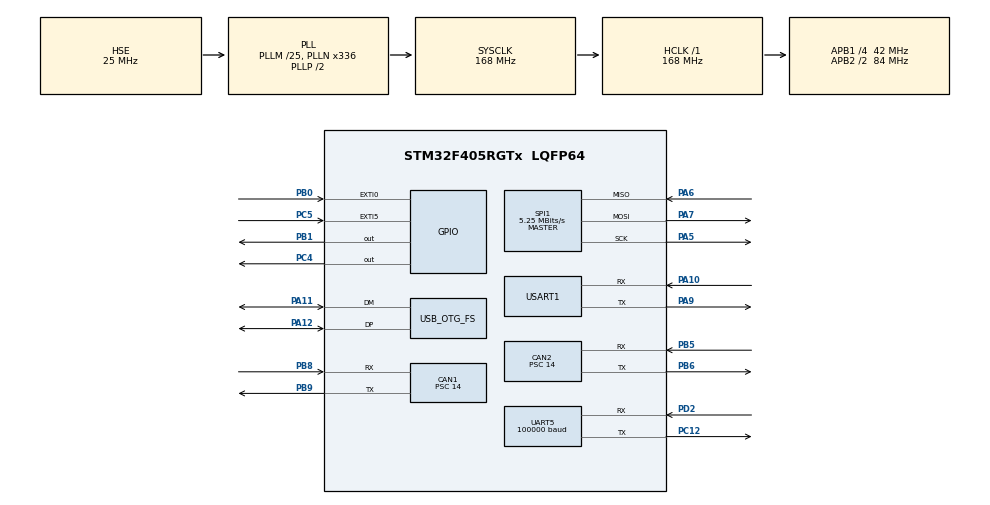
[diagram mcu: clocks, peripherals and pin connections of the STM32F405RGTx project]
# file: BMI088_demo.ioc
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CAN1.CalculateBaudRate=999999
CAN1.CalculateTimeBit=1000
CAN1.CalculateTimeQuantum=333.33333333333337
CAN1.Prescaler=14
CAN2.CalculateBaudRate=999999
CAN2.CalculateTimeBit=1000
CAN2.CalculateTimeQuantum=333.33333333333337
CAN2.Prescaler=14
Dma.Request0=UART5_RX
Dma.UART5_RX.0.Direction=DMA_PERIPH_TO_MEMORY
Dma.UART5_RX.0.FIFOMode=DMA_FIFOMODE_DISABLE
Dma.UART5_RX.0.Instance=DMA1_Stream0
Dma.UART5_RX.0.MemDataAlignment=DMA_MDATAALIGN_BYTE
Dma.UART5_RX.0.MemInc=DMA_MINC_ENABLE
Dma.UART5_RX.0.Mode=DMA_NORMAL
Dma.UART5_RX.0.PeriphDataAlignment=DMA_PDATAALIGN_BYTE
Dma.UART5_RX.0.PeriphInc=DMA_PINC_DISABLE
Dma.UART5_RX.0.Priority=DMA_PRIORITY_VERY_HIGH
FREERTOS.Queues01=BMI088DataQueue,8,4,1,Dynamic,NULL,NULL;VisionDataQueue,16,4,1,Dynamic,NULL,NULL
FREERTOS.Tasks01=UART_Print_Task,10,256,Start_UART_Print_TaskTask,As weak,NULL,Dynamic,NULL,NULL;BMI088_Read_Tas,24,128,Start_BMI088_Read_Task_Task,As weak,NULL,Dynamic,NULL,NULL;VisionProcessTa,25,512,Start_Vision_Process_Task,As weak,NULL,Dynamic,NULL,NULL;CAN_Motor_Task,40,512,Start_CAN_Motor_Task,As weak,NULL,Dynamic,NULL,NULL;RC_Parse_Task,41,512,Start_RC_Parse_Task,As weak,NULL,Dynamic,NULL,NULL;Chassis_CAN_Tas,40,1024,Start_Chassis_CAN_Task,As weak,NULL,Dynamic,NULL,NULL
Mcu.Family=STM32F4
Mcu.Name=STM32F405RGTx
Mcu.Package=LQFP64
NVIC.CAN1_RX0_IRQn=true\:5\:0\:false\:false\:true\:true\:true\:true\:true
NVIC.CAN1_RX1_IRQn=true\:5\:0\:false\:false\:true\:true\:true\:true\:true
NVIC.CAN1_TX_IRQn=true\:5\:0\:false\:false\:true\:true\:true\:true\:true
NVIC.DMA1_Stream0_IRQn=true\:5\:0\:false\:false\:true\:true\:false\:true\:true
NVIC.EXTI0_IRQn=true\:5\:0\:true\:false\:true\:true\:true\:true\:true
NVIC.EXTI9_5_IRQn=true\:5\:0\:true\:false\:true\:true\:true\:true\:true
NVIC.OTG_FS_IRQn=true\:5\:0\:false\:false\:true\:true\:false\:true\:true
NVIC.PriorityGroup=NVIC_PRIORITYGROUP_4
NVIC.TIM1_UP_TIM10_IRQn=true\:15\:0\:false\:false\:true\:false\:false\:true\:true
NVIC.TimeBase=TIM1_UP_TIM10_IRQn
NVIC.TimeBaseIP=TIM1
NVIC.UART5_IRQn=true\:5\:0\:false\:false\:true\:true\:true\:true\:true
PA10.Mode=Asynchronous
PA10.Signal=USART1_RX
PA11.Mode=Device_Only
PA11.Signal=USB_OTG_FS_DM
PA12.Mode=Device_Only
PA12.Signal=USB_OTG_FS_DP
PA13.Mode=Serial_Wire
PA13.Signal=SYS_JTMS-SWDIO
PA14.Mode=Serial_Wire
PA14.Signal=SYS_JTCK-SWCLK
PA5.Mode=Full_Duplex_Master
PA5.Signal=SPI1_SCK
PA6.Mode=Full_Duplex_Master
PA6.Signal=SPI1_MISO
PA7.Mode=Full_Duplex_Master
PA7.Signal=SPI1_MOSI
PA9.Mode=Asynchronous
PA9.Signal=USART1_TX
PB0.GPIO_ModeDefaultEXTI=GPIO_MODE_IT_FALLING
PB0.GPIO_PuPd=GPIO_PULLUP
PB0.Signal=GPXTI0
PB1.GPIO_ModeDefaultOutputPP=GPIO_MODE_OUTPUT_PP
PB1.PinState=GPIO_PIN_SET
PB1.Signal=GPIO_Output
PB5.Mode=CAN_Activate
PB5.Signal=CAN2_RX
PB6.Mode=CAN_Activate
PB6.Signal=CAN2_TX
PB8.Mode=CAN_Activate
PB8.Signal=CAN1_RX
PB9.Mode=CAN_Activate
PB9.Signal=CAN1_TX
PC12.Mode=Asynchronous
PC12.Signal=UART5_TX
PC4.GPIO_ModeDefaultOutputPP=GPIO_MODE_OUTPUT_PP
PC4.PinState=GPIO_PIN_SET
PC4.Signal=GPIO_Output
PC5.GPIO_ModeDefaultEXTI=GPIO_MODE_IT_FALLING
PC5.GPIO_PuPd=GPIO_PULLUP
PC5.Signal=GPXTI5
PD2.Mode=Asynchronous
PD2.Signal=UART5_RX
PH0-OSC_IN.Mode=HSE-External-Oscillator
PH0-OSC_IN.Signal=RCC_OSC_IN
PH1-OSC_OUT.Mode=HSE-External-Oscillator
PH1-OSC_OUT.Signal=RCC_OSC_OUT
ProjectManager.HeapSize=0x200
ProjectManager.StackSize=0x400
ProjectManager.TargetToolchain=CMake
RCC.48MHZClocksFreq_Value=48000000
RCC.AHBFreq_Value=168000000
RCC.APB1CLKDivider=RCC_HCLK_DIV4
RCC.APB1Freq_Value=42000000
RCC.APB1TimFreq_Value=84000000
RCC.APB2CLKDivider=RCC_HCLK_DIV2
RCC.APB2Freq_Value=84000000
RCC.APB2TimFreq_Value=168000000
RCC.CortexFreq_Value=168000000
RCC.HCLKFreq_Value=168000000
RCC.HSE_VALUE=25000000
RCC.HSI_VALUE=16000000
RCC.LSE_VALUE=32768
RCC.PLLM=25
RCC.PLLN=336
RCC.PLLQ=7
RCC.SYSCLKFreq_VALUE=168000000
RCC.SYSCLKSource=RCC_SYSCLKSOURCE_PLLCLK
RCC.VCOOutputFreq_Value=336000000
SPI1.BaudRatePrescaler=SPI_BAUDRATEPRESCALER_16
SPI1.CalculateBaudRate=5.25 MBits/s
SPI1.Direction=SPI_DIRECTION_2LINES
SPI1.Mode=SPI_MODE_MASTER
SPI1.VirtualType=VM_MASTER
UART5.BaudRate=100000
UART5.Mode=MODE_RX
UART5.Parity=PARITY_EVEN
UART5.VirtualMode=Asynchronous
USART1.VirtualMode=VM_ASYNC
USB_DEVICE.CLASS_NAME_FS=CDC
USB_DEVICE.VirtualMode-CDC_FS=Cdc
USB_DEVICE.VirtualModeFS=Cdc_FS
USB_OTG_FS.VirtualMode=Device_Only
VP_FREERTOS_VS_CMSIS_V2.Mode=CMSIS_V2
VP_SYS_VS_tim1.Mode=TIM1
VP_USB_DEVICE_VS_USB_DEVICE_CDC_FS.Mode=CDC_FS
board=custom

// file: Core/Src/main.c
/* USER CODE BEGIN Header */
/**
  ******************************************************************************
  * @file           : main.c
  * @brief          : Main program body
  ******************************************************************************
  * @attention
  *
  * Copyright (c) 2026 STMicroelectronics.
  * All rights reserved.
  *
  * This software is licensed under terms that can be found in the LICENSE file
  * in the root directory of this software component.
  * If no LICENSE file comes with this software, it is provided AS-IS.
  *
  ******************************************************************************
  */
/* USER CODE END Header */
#include "stm32f4xx_hal.h"
#include "main.h"
#include "cmsis_os.h"
#include "can.h"
#include "dma.h"
#include "spi.h"
#include "usart.h"
#include "usb_device.h"
#include "gpio.h"

void SystemClock_Config(void);
void MX_FREERTOS_Init(void);

int main(void)
{

  /* MCU Configuration--------------------------------------------------------*/

  /* Reset of all peripherals, Initializes the Flash interface and the Systick. */
  HAL_Init();

  /* Configure the system clock */
  SystemClock_Config();

  /* Initialize all configured peripherals */
  MX_GPIO_Init();
  MX_DMA_Init();
  MX_SPI1_Init();
  MX_USART1_UART_Init();
  MX_CAN2_Init();
  MX_CAN1_Init();
  MX_UART5_Init();

  /* USER CODE BEGIN 2 */
  MX_USB_DEVICE_Init();
  /* USER CODE END 2 */

  /* Init scheduler */
  osKernelInitialize();  /* Call init function for freertos objects (in cmsis_os2.c) */
  MX_FREERTOS_Init();

  /* Start scheduler */
  osKernelStart();

  /* We should never get here as control is now taken by the scheduler */

  /* Infinite loop */
  while (1)
  {

  }
}

void SystemClock_Config(void)
{
  RCC_OscInitTypeDef RCC_OscInitStruct = {0};
  RCC_ClkInitTypeDef RCC_ClkInitStruct = {0};

  /** Configure the main internal regulator output voltage
  */
  __HAL_RCC_PWR_CLK_ENABLE();
  __HAL_PWR_VOLTAGESCALING_CONFIG(PWR_REGULATOR_VOLTAGE_SCALE1);

  /** Initializes the RCC Oscillators according to the specified parameters
  * in the RCC_OscInitTypeDef structure.
  */
  RCC_OscInitStruct.OscillatorType = RCC_OSCILLATORTYPE_HSE;
  RCC_OscInitStruct.HSEState = RCC_HSE_ON;
  RCC_OscInitStruct.PLL.PLLState = RCC_PLL_ON;
  RCC_OscInitStruct.PLL.PLLSource = RCC_PLLSOURCE_HSE;
  RCC_OscInitStruct.PLL.PLLM = 25;
  RCC_OscInitStruct.PLL.PLLN = 336;
  RCC_OscInitStruct.PLL.PLLP = RCC_PLLP_DIV2;
  RCC_OscInitStruct.PLL.PLLQ = 7;
  if (HAL_RCC_OscConfig(&RCC_OscInitStruct) != HAL_OK)
  {
    Error_Handler();
  }

  /** Initializes the CPU, AHB and APB buses clocks
  */
  RCC_ClkInitStruct.ClockType = RCC_CLOCKTYPE_HCLK|RCC_CLOCKTYPE_SYSCLK
                              |RCC_CLOCKTYPE_PCLK1|RCC_CLOCKTYPE_PCLK2;
  RCC_ClkInitStruct.SYSCLKSource = RCC_SYSCLKSOURCE_PLLCLK;
  RCC_ClkInitStruct.AHBCLKDivider = RCC_SYSCLK_DIV1;
  RCC_ClkInitStruct.APB1CLKDivider = RCC_HCLK_DIV4;
  RCC_ClkInitStruct.APB2CLKDivider = RCC_HCLK_DIV2;

  if (HAL_RCC_ClockConfig(&RCC_ClkInitStruct, FLASH_LATENCY_5) != HAL_OK)
  {
    Error_Handler();
  }
}

void HAL_TIM_PeriodElapsedCallback(TIM_HandleTypeDef *htim)
{
  if (htim->Instance == TIM1)
  {
    HAL_IncTick();
  }
}

void Error_Handler(void)
{
  __disable_irq();
  while (1)
  {
  }
}

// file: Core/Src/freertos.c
/* USER CODE BEGIN Header */
/**
  ******************************************************************************
  * File Name          : freertos.c
  * Description        : Code for freertos applications
  ******************************************************************************
  * @attention
  *
  * Copyright (c) 2026 STMicroelectronics.
  * All rights reserved.
  *
  * This software is licensed under terms that can be found in the LICENSE file
  * in the root directory of this software component.
  * If no LICENSE file comes with this software, it is provided AS-IS.
  *
  ******************************************************************************
  */
/* USER CODE END Header */

#include "FreeRTOS.h"
#include "task.h"
#include "main.h"
#include "cmsis_os.h"

/* Definitions for UART_Print_Task */
osThreadId_t UART_Print_TaskHandle;
const osThreadAttr_t UART_Print_Task_attributes = {
  .name = "UART_Print_Task",
  .stack_size = 256 * 4,
  .priority = (osPriority_t) osPriorityLow2,
};
/* Definitions for BMI088_Read_Tas */
osThreadId_t BMI088_Read_TasHandle;
const osThreadAttr_t BMI088_Read_Tas_attributes = {
  .name = "BMI088_Read_Tas",
  .stack_size = 128 * 4,
  .priority = (osPriority_t) osPriorityNormal,
};
/* Definitions for VisionProcessTa */
osThreadId_t VisionProcessTaHandle;
const osThreadAttr_t VisionProcessTa_attributes = {
  .name = "VisionProcessTa",
  .stack_size = 512 * 4,
  .priority = (osPriority_t) osPriorityNormal1,
};
/* Definitions for CAN_Motor_Task */
osThreadId_t CAN_Motor_TaskHandle;
const osThreadAttr_t CAN_Motor_Task_attributes = {
  .name = "CAN_Motor_Task",
  .stack_size = 512 * 4,
  .priority = (osPriority_t) osPriorityHigh,
};
/* Definitions for RC_Parse_Task */
osThreadId_t RC_Parse_TaskHandle;
const osThreadAttr_t RC_Parse_Task_attributes = {
  .name = "RC_Parse_Task",
  .stack_size = 512 * 4,
  .priority = (osPriority_t) osPriorityHigh1,
};
/* Definitions for Chassis_CAN_Tas */
osThreadId_t Chassis_CAN_TasHandle;
const osThreadAttr_t Chassis_CAN_Tas_attributes = {
  .name = "Chassis_CAN_Tas",
  .stack_size = 1024 * 4,
  .priority = (osPriority_t) osPriorityHigh,
};

/* Definitions for BMI088DataQueue */
osMessageQueueId_t BMI088DataQueueHandle;
const osMessageQueueAttr_t BMI088DataQueue_attributes = {
  .name = "BMI088DataQueue"
};
/* Definitions for VisionDataQueue */
osMessageQueueId_t VisionDataQueueHandle;
const osMessageQueueAttr_t VisionDataQueue_attributes = {
  .name = "VisionDataQueue"
};

void Start_UART_Print_TaskTask(void *argument);
void Start_BMI088_Read_Task_Task(void *argument);
void Start_Vision_Process_Task(void *argument);
void Start_CAN_Motor_Task(void *argument);
void Start_RC_Parse_Task(void *argument);
void Start_Chassis_CAN_Task(void *argument);

extern void MX_USB_DEVICE_Init(void);
void MX_FREERTOS_Init(void); /* (MISRA C 2004 rule 8.1) */

void MX_FREERTOS_Init(void) {

  /* Create the queue(s) */
  /* creation of BMI088DataQueue */
  BMI088DataQueueHandle = osMessageQueueNew (8, 4, &BMI088DataQueue_attributes);

  /* creation of VisionDataQueue */
  VisionDataQueueHandle = osMessageQueueNew (16, 4, &VisionDataQueue_attributes);

  /* Create the thread(s) */
  /* creation of UART_Print_Task */
  UART_Print_TaskHandle = osThreadNew(Start_UART_Print_TaskTask, NULL, &UART_Print_Task_attributes);

  /* creation of BMI088_Read_Tas */
  BMI088_Read_TasHandle = osThreadNew(Start_BMI088_Read_Task_Task, NULL, &BMI088_Read_Tas_attributes);

  /* creation of VisionProcessTa */
  VisionProcessTaHandle = osThreadNew(Start_Vision_Process_Task, NULL, &VisionProcessTa_attributes);

  /* creation of CAN_Motor_Task */
  CAN_Motor_TaskHandle = osThreadNew(Start_CAN_Motor_Task, NULL, &CAN_Motor_Task_attributes);

  /* creation of RC_Parse_Task */
  RC_Parse_TaskHandle = osThreadNew(Start_RC_Parse_Task, NULL, &RC_Parse_Task_attributes);

  /* creation of Chassis_CAN_Tas */
  Chassis_CAN_TasHandle = osThreadNew(Start_Chassis_CAN_Task, NULL, &Chassis_CAN_Tas_attributes);

}

__weak void Start_UART_Print_TaskTask(void *argument)
{
  /* init code for USB_DEVICE */
  MX_USB_DEVICE_Init();
  for(;;)
  {
    osDelay(1);
  }
}

__weak void Start_BMI088_Read_Task_Task(void *argument)
{
  for(;;)
  {
    osDelay(1);
  }
}

__weak void Start_Vision_Process_Task(void *argument)
{
  for(;;)
  {
    osDelay(1);
  }
}

__weak void Start_CAN_Motor_Task(void *argument)
{
  for(;;)
  {
    osDelay(1);
  }
}

__weak void Start_RC_Parse_Task(void *argument)
{
  for(;;)
  {
    osDelay(1);
  }
}

__weak void Start_Chassis_CAN_Task(void *argument)
{
  for(;;)
  {
    osDelay(1);
  }
}
